# aes256 register map
Vendor: Texas Instruments
Peripheral module from a debugger description file (folder MSP432).
Registers are 16-bit, read-write, no defined reset value unless marked. A register's access mark holds for its fields unless they carry their own. Offsets are as the file gives them; lines under a group give offsets from that group; [hi:lo] are bit positions; {n}, {i} and the like mark numbered series; 'fields as' and 'values as' point back to an identical list; <NAME> marks a mode.

## AES256
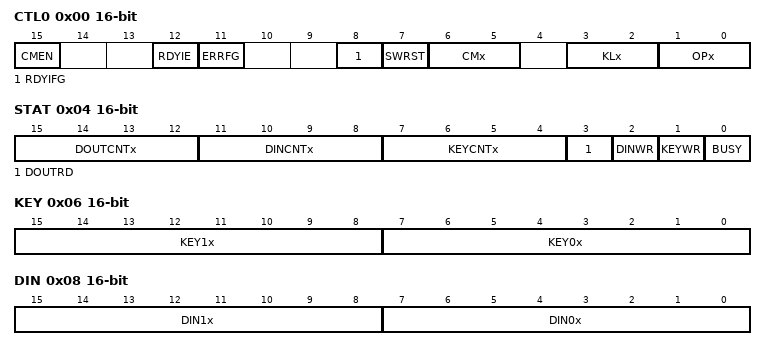
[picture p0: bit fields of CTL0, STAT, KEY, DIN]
0x00 CTL0 — AES Accelerator Control Register 0
  [15] CMEN — AESCMEN enables the support of the ciphermodes ECB, CBC, OFB an
    0=CMEN__0 (No DMA triggers are generated); 1=CMEN__1 (DMA ciphermode support operation is enabled and the correspondi)
  [12] RDYIE — AES ready interrupt enable
    0=RDYIE__0 (Interrupt disabled); 1=RDYIE__1 (Interrupt enabled)
  [11] ERRFG — AES error flag
    0=ERRFG__0 (No error); 1=ERRFG__1 (Error occurred)
  [8] RDYIFG — AES ready interrupt flag
    0=RDYIFG__0 (No interrupt pending); 1=RDYIFG__1 (Interrupt pending)
  [7] SWRST — AES software reset
    0=SWRST__0 (No reset); 1=SWRST__1 (Reset AES accelerator module)
  [6:5] CMx — AES cipher mode select
    0=CM__0 (ECB); 1=CM__1 (CBC); 2=CM__2 (OFB); 3=CM__3 (CFB)
  [3:2] KLx — AES key length
    0=KL__0 (AES128. The key size is 128 bit); 1=KL__1 (AES192. The key size is 192 bit.); 2=KL__2 (AES256. The key size is 256 bit)
  [1:0] OPx — AES operation
    0=OP__0 (Encryption); 1=OP__1 (Decryption. The provided key is the same key used for encryption); 2=OP__2 (Generate first round key required for decryption); 3=OP__3 (Decryption)
0x02 CTL1 — AES Accelerator Control Register 1
  [7:0] BLKCNTx — Cipher Block Counter
0x04 STAT — AES Accelerator Status Register
  [15:12] DOUTCNTx — Bytes read via AESADOUT
  [11:8] DINCNTx — Bytes written via AESADIN, AESAXDIN or AESAXIN
  [7:4] KEYCNTx — Bytes written via AESAKEY for AESKLx=00, half-words written via
  [3] DOUTRD — All 16 bytes read from AESADOUT
    0=DOUTRD__0 (Not all bytes read); 1=DOUTRD__1 (All bytes read)
  [2] DINWR — All 16 bytes written to AESADIN, AESAXDIN or AESAXIN
    0=DINWR__0 (Not all bytes written); 1=DINWR__1 (All bytes written)
  [1] KEYWR — All 16 bytes written to AESAKEY
    0=KEYWR__0 (Not all bytes written); 1=KEYWR__1 (All bytes written)
  [0] BUSY — AES accelerator module busy; encryption, decryption, or key gen
    0=BUSY__0 (Not busy); 1=BUSY__1
0x06 KEY — AES Accelerator Key Register
  [15:8] KEY1x — AES key byte n+1 when AESAKEY is written as half-word
  [7:0] KEY0x — AES key byte n when AESAKEY is written as half-word
0x08 DIN — AES Accelerator Data In Register
  [15:8] DIN1x — AES data in byte n+1 when AESADIN is written as half-word
  [7:0] DIN0x — AES data in byte n when AESADIN is written as half-word
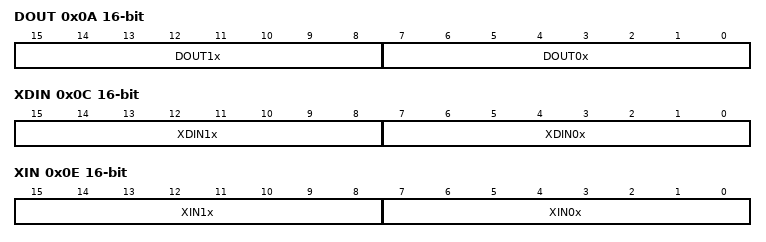
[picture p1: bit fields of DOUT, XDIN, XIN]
0x0A DOUT — AES Accelerator Data Out Register
  [15:8] DOUT1x — AES data out byte n+1 when AESADOUT is read as half-word
  [7:0] DOUT0x — AES data out byte n when AESADOUT is read as half-word
0x0C XDIN — AES Accelerator XORed Data In Register
  [15:8] XDIN1x — AES data in byte n+1 when AESAXDIN is written as half-word
  [7:0] XDIN0x — AES data in byte n when AESAXDIN is written as half-word
0x0E XIN — AES Accelerator XORed Data In Register
  [15:8] XIN1x — AES data in byte n+1 when AESAXIN is written as half-word
  [7:0] XIN0x — AES data in byte n when AESAXIN is written as half-word
